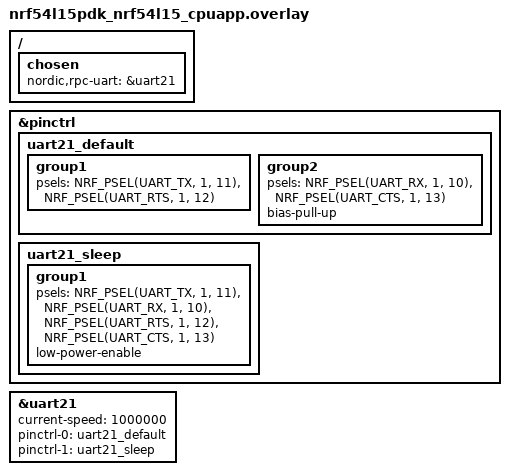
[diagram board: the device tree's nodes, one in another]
/* Copyright (c) 2024 Nordic Semiconductor ASA
 *
 * SPDX-License-Identifier: LicenseRef-Nordic-5-Clause
 */

 / {
	chosen {
		nordic,rpc-uart = &uart21;
	};
};

&pinctrl {
	uart21_default: uart21_default {
		group1 {
			psels = <NRF_PSEL(UART_TX, 1, 11)>,
				<NRF_PSEL(UART_RTS, 1, 12)>;
		};
		group2 {
			psels = <NRF_PSEL(UART_RX, 1, 10)>,
				<NRF_PSEL(UART_CTS, 1, 13)>;
			bias-pull-up;
		};
	};

	uart21_sleep: uart21_sleep {
		group1 {
			psels = <NRF_PSEL(UART_TX, 1, 11)>,
				<NRF_PSEL(UART_RX, 1, 10)>,
				<NRF_PSEL(UART_RTS, 1, 12)>,
				<NRF_PSEL(UART_CTS, 1, 13)>;
			low-power-enable;
		};
	};

};

&uart21 {
	status = "okay";
	current-speed = <1000000>;
	pinctrl-0 = <&uart21_default>;
	pinctrl-1 = <&uart21_sleep>;
	pinctrl-names = "default", "sleep";
};
